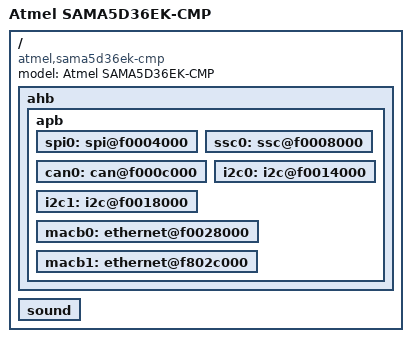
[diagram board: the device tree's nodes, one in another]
// SPDX-License-Identifier: (GPL-2.0+ OR MIT)
/*
 * sama5d36ek_cmp.dts - Device Tree file for SAMA5D36-EK CMP board
 *
 *  Copyright (C) 2016 Atmel,
 */
/dts-v1/;
#include "sama5d36.dtsi"
#include "sama5d3xmb_cmp.dtsi"

/ {
	model = "Atmel SAMA5D36EK-CMP";
	compatible = "atmel,sama5d36ek-cmp", "atmel,sama5d3xmb-cmp", "atmel,sama5d3xcm-cmp", "atmel,sama5d36", "atmel,sama5d3", "atmel,sama5";

	ahb {
		apb {
			spi0: spi@f0004000 {
				status = "okay";
			};

			ssc0: ssc@f0008000 {
				status = "okay";
			};

			can0: can@f000c000 {
				status = "okay";
			};

			i2c0: i2c@f0014000 {
				status = "okay";
			};

			i2c1: i2c@f0018000 {
				status = "okay";
			};

			macb0: ethernet@f0028000 {
				status = "okay";
			};

			macb1: ethernet@f802c000 {
				status = "okay";
			};
		};
	};

	sound {
		status = "okay";
	};
};
